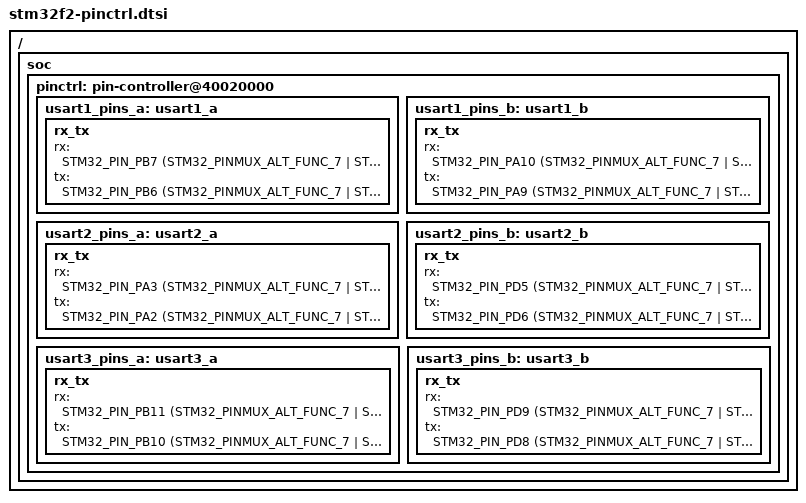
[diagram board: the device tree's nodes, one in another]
/*
 * Copyright (c) 2018 qianfan Zhao
 *
 * SPDX-License-Identifier: Apache-2.0
 */

#include <dt-bindings/pinctrl/stm32-pinctrl.h>

/ {
	soc {
		pinctrl: pin-controller@40020000 {
			usart1_pins_a: usart1_a {
				rx_tx {
					rx = <STM32_PIN_PB7 (STM32_PINMUX_ALT_FUNC_7 | STM32_PUPDR_NO_PULL)>;
					tx = <STM32_PIN_PB6 (STM32_PINMUX_ALT_FUNC_7 | STM32_PUSHPULL_NOPULL)>;
				};
			};
			usart1_pins_b: usart1_b {
				rx_tx {
					rx = <STM32_PIN_PA10 (STM32_PINMUX_ALT_FUNC_7 | STM32_PUPDR_NO_PULL)>;
					tx = <STM32_PIN_PA9 (STM32_PINMUX_ALT_FUNC_7 | STM32_PUSHPULL_NOPULL)>;
				};
			};
			usart2_pins_a: usart2_a {
				rx_tx {
					rx = <STM32_PIN_PA3 (STM32_PINMUX_ALT_FUNC_7 | STM32_PUPDR_NO_PULL)>;
					tx = <STM32_PIN_PA2 (STM32_PINMUX_ALT_FUNC_7 | STM32_PUSHPULL_NOPULL)>;
				};
			};
			usart2_pins_b: usart2_b {
				rx_tx {
					rx = <STM32_PIN_PD5 (STM32_PINMUX_ALT_FUNC_7 | STM32_PUPDR_NO_PULL)>;
					tx = <STM32_PIN_PD6 (STM32_PINMUX_ALT_FUNC_7 | STM32_PUSHPULL_NOPULL)>;
				};
			};
			usart3_pins_a: usart3_a {
				rx_tx {
					rx = <STM32_PIN_PB11 (STM32_PINMUX_ALT_FUNC_7 | STM32_PUPDR_NO_PULL)>;
					tx = <STM32_PIN_PB10 (STM32_PINMUX_ALT_FUNC_7 | STM32_PUSHPULL_NOPULL)>;
				};
			};
			usart3_pins_b: usart3_b {
				rx_tx {
					rx = <STM32_PIN_PD9 (STM32_PINMUX_ALT_FUNC_7 | STM32_PUPDR_NO_PULL)>;
					tx = <STM32_PIN_PD8 (STM32_PINMUX_ALT_FUNC_7 | STM32_PUSHPULL_NOPULL)>;
				};
			};
		};
	};
};
